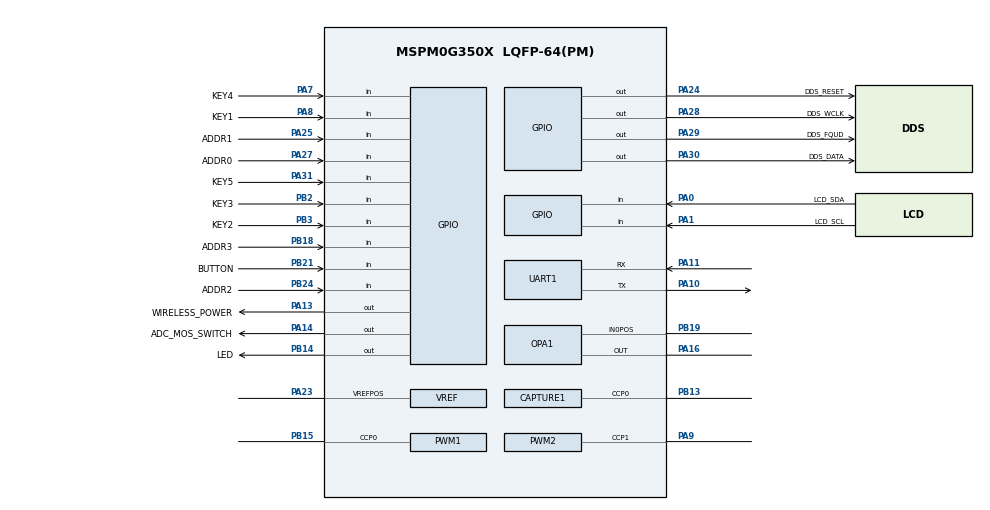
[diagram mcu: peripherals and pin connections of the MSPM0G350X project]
// @cliArgs --product "C:/ti/mspm0_sdk_2_01_00_03/.metadata/product.json" --device "MSPM0G350X" --package "LQFP-64(PM)" --part "Default"
// @versions {"tool":"1.20.0+3587"}

/**
 * Import the modules used in this configuration.
 */
const ADC12  = scripting.addModule("/ti/driverlib/ADC12", {}, false);
const ADC121 = ADC12.addInstance();
const ADC122 = ADC12.addInstance();
const Board  = scripting.addModule("/ti/driverlib/Board");
const CAPTURE = scripting.addModule("/ti/driverlib/CAPTURE", {}, false);
const CAPTURE1 = CAPTURE.addInstance();
const COMP   = scripting.addModule("/ti/driverlib/COMP", {}, false);
const COMP1  = COMP.addInstance();
const DAC12  = scripting.addModule("/ti/driverlib/DAC12");
const DMA    = scripting.addModule("/ti/driverlib/DMA");
const GPIO   = scripting.addModule("/ti/driverlib/GPIO", {}, false);
const GPIO1  = GPIO.addInstance();
const GPIO2  = GPIO.addInstance();
const GPIO3  = GPIO.addInstance();
const GPIO4  = GPIO.addInstance();
const GPIO5  = GPIO.addInstance();
const GPIO6  = GPIO.addInstance();
const OPA    = scripting.addModule("/ti/driverlib/OPA", {}, false);
const OPA1   = OPA.addInstance();
const PWM    = scripting.addModule("/ti/driverlib/PWM", {}, false);
const PWM1   = PWM.addInstance();
const PWM2   = PWM.addInstance();
const RTC    = scripting.addModule("/ti/driverlib/RTC");
const SYSCTL = scripting.addModule("/ti/driverlib/SYSCTL");
const TIMER  = scripting.addModule("/ti/driverlib/TIMER", {}, false);
const TIMER1 = TIMER.addInstance();
const TIMER2 = TIMER.addInstance();
const TIMER3 = TIMER.addInstance();
const UART   = scripting.addModule("/ti/driverlib/UART", {}, false);
const UART1  = UART.addInstance();
const VREF   = scripting.addModule("/ti/driverlib/VREF");

/**
 * Write custom configuration values to the imported modules.
 */
const gate8  = system.clockTree["MFPCLKGATE"];
gate8.enable = true;

ADC121.$name                          = "ADC12_0";
ADC121.repeatMode                     = true;
ADC121.trigSrc                        = "DL_ADC12_TRIG_SRC_EVENT";
ADC121.adcMem0chansel                 = "DL_ADC12_INPUT_CHAN_7";
ADC121.adcMem0vref                    = "VREF";
ADC121.sampleTime0                    = "500ns";
ADC121.powerDownMode                  = "DL_ADC12_POWER_DOWN_MODE_MANUAL";
ADC121.configureDMA                   = true;
ADC121.sampCnt                        = 1;
ADC121.enabledDMATriggers             = ["DL_ADC12_DMA_MEM0_RESULT_LOADED"];
ADC121.enabledInterrupts              = ["DL_ADC12_INTERRUPT_DMA_DONE"];
ADC121.subChanID                      = 1;
ADC121.peripheral.$assign             = "ADC0";
ADC121.peripheral.adcPin7.$assign     = "PA22";
ADC121.adcPin7Config.$name            = "ti_driverlib_gpio_GPIOPinGeneric0";
ADC121.DMA_CHANNEL.$name              = "DMA_CH0";
ADC121.DMA_CHANNEL.addressMode        = "f2b";
ADC121.DMA_CHANNEL.srcLength          = "HALF_WORD";
ADC121.DMA_CHANNEL.dstLength          = "HALF_WORD";
ADC121.DMA_CHANNEL.transferMode       = "FULL_CH_REPEAT_SINGLE";
ADC121.DMA_CHANNEL.peripheral.$assign = "DMA_CH0";

ADC122.$name                          = "ADC12_1";
ADC122.repeatMode                     = true;
ADC122.trigSrc                        = "DL_ADC12_TRIG_SRC_EVENT";
ADC122.adcMem0chansel                 = "DL_ADC12_INPUT_CHAN_7";
ADC122.adcMem0vref                    = "VREF";
ADC122.sampleTime0                    = "500ns";
ADC122.powerDownMode                  = "DL_ADC12_POWER_DOWN_MODE_MANUAL";
ADC122.configureDMA                   = true;
ADC122.sampCnt                        = 1;
ADC122.enabledDMATriggers             = ["DL_ADC12_DMA_MEM0_RESULT_LOADED"];
ADC122.enabledInterrupts              = ["DL_ADC12_INTERRUPT_DMA_DONE"];
ADC122.subChanID                      = 2;
ADC122.peripheral.$assign             = "ADC1";
ADC122.peripheral.adcPin7.$assign     = "PA21";
ADC122.adcPin7Config.$name            = "ti_driverlib_gpio_GPIOPinGeneric1";
ADC122.DMA_CHANNEL.$name              = "DMA_CH1";
ADC122.DMA_CHANNEL.addressMode        = "f2b";
ADC122.DMA_CHANNEL.srcLength          = "HALF_WORD";
ADC122.DMA_CHANNEL.dstLength          = "HALF_WORD";
ADC122.DMA_CHANNEL.transferMode       = "FULL_CH_REPEAT_SINGLE";
ADC122.DMA_CHANNEL.peripheral.$assign = "DMA_CH1";


DAC12.dacOutputPinEn     = true;
DAC12.dacConfigureDMA    = true;
DAC12.dacSampleTimerEn   = false;
DAC12.dacSampleTimerRate = "1M";
DAC12.dacOutput12        = 2048;
DAC12.dacFIFOEn          = true;
DAC12.dacAmplifier       = "ON";
DAC12.dacFIFOThresh      = "TWO_QTRS_EMPTY";
DAC12.DMA_CHANNEL.$name  = "DMA_DAC";
DAC12.DMA_CHANNEL.transferMode = "FULL_CH_REPEAT_SINGLE";
DAC12.DMA_CHANNEL.addressMode = "b2f";
DAC12.DMA_CHANNEL.srcLength = "HALF_WORD";
DAC12.DMA_CHANNEL.dstLength = "HALF_WORD";
DAC12.DMA_CHANNEL.peripheral.$assign = "DMA_CH2";
DAC12.OutPinConfig.$name = "ti_driverlib_gpio_GPIOPinGeneric4";


GPIO1.$name                              = "KEY";
GPIO1.associatedPins.create(5);
GPIO1.associatedPins[0].$name            = "KEY1";
GPIO1.associatedPins[0].direction        = "INPUT";
GPIO1.associatedPins[0].assignedPort     = "PORTA";
GPIO1.associatedPins[0].assignedPin      = "8";
GPIO1.associatedPins[0].internalResistor = "PULL_UP";
GPIO1.associatedPins[0].pin.$assign      = "PA8";
GPIO1.associatedPins[1].$name            = "KEY2";
GPIO1.associatedPins[1].direction        = "INPUT";
GPIO1.associatedPins[1].assignedPort     = "PORTB";
GPIO1.associatedPins[1].assignedPin      = "3";
GPIO1.associatedPins[1].internalResistor = "PULL_UP";
GPIO1.associatedPins[1].pin.$assign      = "PB3";
GPIO1.associatedPins[2].$name            = "KEY3";
GPIO1.associatedPins[2].direction        = "INPUT";
GPIO1.associatedPins[2].assignedPort     = "PORTB";
GPIO1.associatedPins[2].assignedPin      = "2";
GPIO1.associatedPins[2].internalResistor = "PULL_UP";
GPIO1.associatedPins[2].pin.$assign      = "PB2";
GPIO1.associatedPins[3].$name            = "KEY4";
GPIO1.associatedPins[3].direction        = "INPUT";
GPIO1.associatedPins[3].assignedPort     = "PORTA";
GPIO1.associatedPins[3].assignedPin      = "7";
GPIO1.associatedPins[3].internalResistor = "PULL_UP";
GPIO1.associatedPins[3].pin.$assign      = "PA7";
GPIO1.associatedPins[4].$name            = "KEY5";
GPIO1.associatedPins[4].direction        = "INPUT";
GPIO1.associatedPins[4].assignedPort     = "PORTA";
GPIO1.associatedPins[4].assignedPin      = "31";
GPIO1.associatedPins[4].internalResistor = "PULL_UP";
GPIO1.associatedPins[4].pin.$assign      = "PA31";

GPIO2.$name                                      = "KEY_LED";
GPIO2.associatedPins.create(2);
GPIO2.associatedPins[0].$name                    = "LED";
GPIO2.associatedPins[0].direction                = "OUTPUT";
GPIO2.associatedPins[0].initialValue             = "CLEARED";
GPIO2.associatedPins[0].assignedPort             = "PORTB";
GPIO2.associatedPins[0].assignedPortSegment      = "Lower";
GPIO2.associatedPins[0].assignedPin              = "14";
GPIO2.associatedPins[0].pin.$assign              = "PB14";
GPIO2.associatedPins[1].$name                    = "BUTTON";
GPIO2.associatedPins[1].direction                = "INPUT";
GPIO2.associatedPins[1].internalResistor         = "PULL_UP";
GPIO2.associatedPins[1].hysteresisControl        = "DISABLE";
GPIO2.associatedPins[1].assignedPort             = "PORTB";
GPIO2.associatedPins[1].assignedPortSegment      = "Upper";
GPIO2.associatedPins[1].assignedPin              = "21";
GPIO2.associatedPins[1].pin.$assign              = "PB21";

/* MSP-LITO-G3507 external OLED bus; R7/R8 provide 2.2 kOhm pulls to 3.3 V. */
GPIO3.$name                                      = "I2C_LCD_PINS";
GPIO3.associatedPins.create(2);
GPIO3.associatedPins[0].$name                    = "LCD_SDA";
GPIO3.associatedPins[0].direction                = "INPUT";
GPIO3.associatedPins[0].hysteresisControl        = "DISABLE";
GPIO3.associatedPins[0].assignedPort             = "PORTA";
GPIO3.associatedPins[0].assignedPortSegment      = "Lower";
GPIO3.associatedPins[0].assignedPin              = "0";
GPIO3.associatedPins[0].pin.$assign              = "PA0";
GPIO3.associatedPins[1].$name                    = "LCD_SCL";
GPIO3.associatedPins[1].direction                = "INPUT";
GPIO3.associatedPins[1].hysteresisControl        = "DISABLE";
GPIO3.associatedPins[1].assignedPort             = "PORTA";
GPIO3.associatedPins[1].assignedPortSegment      = "Lower";
GPIO3.associatedPins[1].assignedPin              = "1";
GPIO3.associatedPins[1].pin.$assign              = "PA1";

/* Active low-power measurement board controls.  PA13 and PA14 are not
 * available to the legacy AD9833 backend in this hardware profile. */
GPIO4.$name                                      = "BOARD_CONTROL";
GPIO4.associatedPins.create(2);
GPIO4.associatedPins[0].$name                    = "WIRELESS_POWER";
GPIO4.associatedPins[0].direction                = "OUTPUT";
GPIO4.associatedPins[0].initialValue             = "CLEARED";
GPIO4.associatedPins[0].assignedPort             = "PORTA";
GPIO4.associatedPins[0].assignedPortSegment      = "Lower";
GPIO4.associatedPins[0].assignedPin              = "13";
GPIO4.associatedPins[0].pin.$assign              = "PA13";
GPIO4.associatedPins[1].$name                    = "ADC_MOS_SWITCH";
GPIO4.associatedPins[1].direction                = "OUTPUT";
GPIO4.associatedPins[1].initialValue             = "CLEARED";
GPIO4.associatedPins[1].assignedPort             = "PORTA";
GPIO4.associatedPins[1].assignedPortSegment      = "Lower";
GPIO4.associatedPins[1].assignedPin              = "14";
GPIO4.associatedPins[1].pin.$assign              = "PA14";

GPIO5.$name                                      = "ADDR_CODE";
GPIO5.associatedPins.create(4);
GPIO5.associatedPins[0].$name                    = "ADDR0";
GPIO5.associatedPins[0].direction                = "INPUT";
GPIO5.associatedPins[0].internalResistor         = "PULL_DOWN";
GPIO5.associatedPins[0].assignedPort             = "PORTA";
GPIO5.associatedPins[0].assignedPin              = "27";
GPIO5.associatedPins[0].pin.$assign              = "PA27";
GPIO5.associatedPins[1].$name                    = "ADDR1";
GPIO5.associatedPins[1].direction                = "INPUT";
GPIO5.associatedPins[1].internalResistor         = "PULL_DOWN";
GPIO5.associatedPins[1].assignedPort             = "PORTA";
GPIO5.associatedPins[1].assignedPin              = "25";
GPIO5.associatedPins[1].pin.$assign              = "PA25";
GPIO5.associatedPins[2].$name                    = "ADDR2";
GPIO5.associatedPins[2].direction                = "INPUT";
GPIO5.associatedPins[2].internalResistor         = "PULL_DOWN";
GPIO5.associatedPins[2].assignedPort             = "PORTB";
GPIO5.associatedPins[2].assignedPortSegment      = "Upper";
GPIO5.associatedPins[2].assignedPin              = "24";
GPIO5.associatedPins[2].pin.$assign              = "PB24";
GPIO5.associatedPins[3].$name                    = "ADDR3";
GPIO5.associatedPins[3].direction                = "INPUT";
GPIO5.associatedPins[3].internalResistor         = "PULL_DOWN";
GPIO5.associatedPins[3].assignedPort             = "PORTB";
GPIO5.associatedPins[3].assignedPortSegment      = "Upper";
GPIO5.associatedPins[3].assignedPin              = "18";
GPIO5.associatedPins[3].pin.$assign              = "PB18";

/* External DDS (AD9850-style, dropped module) software-serial control lines.
 * All four pins are free on the MSP-LITO-G3507.  Change only if the module
 * needs different wiring; keep pinmux ownership in SysConfig. */
GPIO6.$name                                      = "DDS_CTRL";
GPIO6.associatedPins.create(4);
GPIO6.associatedPins[0].$name                    = "DDS_WCLK";
GPIO6.associatedPins[0].direction                = "OUTPUT";
GPIO6.associatedPins[0].initialValue             = "CLEARED";
GPIO6.associatedPins[0].assignedPort             = "PORTA";
GPIO6.associatedPins[0].assignedPortSegment      = "Upper";
GPIO6.associatedPins[0].assignedPin              = "28";
GPIO6.associatedPins[0].pin.$assign              = "PA28";
GPIO6.associatedPins[1].$name                    = "DDS_FQUD";
GPIO6.associatedPins[1].direction                = "OUTPUT";
GPIO6.associatedPins[1].initialValue             = "CLEARED";
GPIO6.associatedPins[1].assignedPort             = "PORTA";
GPIO6.associatedPins[1].assignedPortSegment      = "Upper";
GPIO6.associatedPins[1].assignedPin              = "29";
GPIO6.associatedPins[1].pin.$assign              = "PA29";
GPIO6.associatedPins[2].$name                    = "DDS_DATA";
GPIO6.associatedPins[2].direction                = "OUTPUT";
GPIO6.associatedPins[2].initialValue             = "CLEARED";
GPIO6.associatedPins[2].assignedPort             = "PORTA";
GPIO6.associatedPins[2].assignedPortSegment      = "Upper";
GPIO6.associatedPins[2].assignedPin              = "30";
GPIO6.associatedPins[2].pin.$assign              = "PA30";
GPIO6.associatedPins[3].$name                    = "DDS_RESET";
GPIO6.associatedPins[3].direction                = "OUTPUT";
GPIO6.associatedPins[3].initialValue             = "CLEARED";
GPIO6.associatedPins[3].assignedPort             = "PORTA";
GPIO6.associatedPins[3].assignedPortSegment      = "Upper";
GPIO6.associatedPins[3].assignedPin              = "24";
GPIO6.associatedPins[3].pin.$assign              = "PA24";

SYSCTL.forceDefaultClkConfig = true;
SYSCTL.clockTreeEn           = true;
SYSCTL.MFPCLKEn              = true;
SYSCTL.LFCLKSource           = "LFXT";
SYSCTL.validateClkStatus     = false;
/* MSPM0G3507 legal default clock tree: SYSOSC -> MCLK/BUSCLK/CPUCLK at 32 MHz.
 * The board's populated 100 kOhm 0.1% ROSC is enabled by BoardClock_Init().
 * LFCLK runs from the on-board 32.768 kHz LFXT (PA3/PA4) to clock the RTC. */
const muxLfclkIn   = system.clockTree["EXLFMUX"];
muxLfclkIn.inputSelect = "EXLFMUX_XTAL";
const muxLfxt      = system.clockTree["LFXTMUX"];
muxLfxt.inputSelect = "LFXTMUX_TRUE";
const pinLfxt      = system.clockTree["LFXT"];
pinLfxt.enable     = true;
pinLfxt.inputFreq  = 32;

VREF.profile             = "INT_2_5_V";
VREF.vrefPosPinConfig.$name = "ti_driverlib_gpio_GPIOPinGeneric7";
VREF.peripheral.$assign  = "VREF";
VREF.peripheral.vrefPosPin.$assign = "PA23";

TIMER1.$name                       = "ADC_SAMPLE_TIMER";
TIMER1.timerMode                   = "PERIODIC";
TIMER1.timerStartTimer             = false;
TIMER1.timerPeriod                 = "78.125 us";
TIMER1.event1PublisherChannel      = 1;
TIMER1.event1ControllerInterruptEn = ["ZERO_EVENT"];
TIMER1.event2PublisherChannel      = 2;
TIMER1.event2ControllerInterruptEn = ["ZERO_EVENT"];
TIMER1.peripheral.$assign          = "TIMG0";

TIMER3.$name              = "LP_WAKE_TIMER";
TIMER3.timerMode          = "PERIODIC";
TIMER3.timerStartTimer    = false;
TIMER3.timerClkSrc        = "LFCLK";
TIMER3.timerPeriod        = "500 ms";
TIMER3.interrupts         = ["ZERO"];
TIMER3.peripheral.$assign = "TIMG8";

UART1.$name                            = "UART_DEBUG";
UART1.targetBaudRate                   = 115200;
UART1.enableFIFO                       = true;
UART1.enabledInterrupts                = ["RX"];
UART1.peripheral.$assign               = "UART0";
UART1.peripheral.rxPin.$assign         = "PA11";
UART1.peripheral.txPin.$assign         = "PA10";
UART1.txPinConfig.$name                = "ti_driverlib_gpio_GPIOPinGeneric2";
UART1.txPinConfig.direction            = scripting.forceWrite("OUTPUT");
UART1.txPinConfig.hideOutputInversion  = scripting.forceWrite(false);
UART1.txPinConfig.onlyInternalResistor = scripting.forceWrite(false);
UART1.txPinConfig.passedPeripheralType = scripting.forceWrite("Digital");
UART1.rxPinConfig.$name                = "ti_driverlib_gpio_GPIOPinGeneric3";
UART1.rxPinConfig.hideOutputInversion  = scripting.forceWrite(false);
UART1.rxPinConfig.onlyInternalResistor = scripting.forceWrite(false);
UART1.rxPinConfig.passedPeripheralType = scripting.forceWrite("Digital");

/* Frequency meter: TIMG12 32-bit PERIOD capture on PB13 (free pin).
 * Period capture measures the time between two consecutive input edges in
 * hardware, so no ISR reload is needed and interrupt latency does not skew
 * the measurement (unlike EDGE_TIME which needs a manual reload). */
CAPTURE1.$name                      = "FREQ_CAPTURE";
CAPTURE1.timerClkSrc                = "BUSCLK";
CAPTURE1.timerClkDiv                = 1;
CAPTURE1.timerClkPrescale           = 1;
CAPTURE1.timerPeriod                = "1 s";
CAPTURE1.captMode                   = "PERIOD_CAPTURE";
CAPTURE1.interrupts                 = ["CC0_DN","ZERO"];
CAPTURE1.peripheral.$assign         = "TIMG12";
CAPTURE1.peripheral.ccp0Pin.$assign = "PB13";
CAPTURE1.ccp0PinConfig.$name        = "ti_driverlib_gpio_GPIOPinFreqCap0";

/* Square-wave generator: TIMG7 PWM edge mode, 50% duty, PB15 out (free pin). */
PWM1.$name                      = "SQUARE_TIMER";
PWM1.clockPrescale              = 1;
PWM1.timerCount                 = 32000;
PWM1.ccIndex                    = [0];
PWM1.peripheral.$assign         = "TIMG7";
PWM1.peripheral.ccp0Pin.$assign = "PB15";
PWM1.ccp0PinConfig.$name        = "ti_driverlib_gpio_GPIOPinSquare0";
PWM1.PWM_CHANNEL_0.$name        = "ti_driverlib_pwm_PWMTimerSquareCC0";
PWM1.PWM_CHANNEL_0.dutyCycle    = 50;
PWM1.PWM_CHANNEL_0.ccValue      = 16000;

/* General PWM output: TIMA0 CCP1 on PA9 (free pin). */
PWM2.$name                      = "PWM_TIMER";
PWM2.clockPrescale              = 1;
PWM2.timerCount                 = 32000;
PWM2.ccIndex                    = [1];
PWM2.peripheral.$assign         = "TIMA0";
PWM2.peripheral.ccp1Pin.$assign = "PA9";
PWM2.ccp1PinConfig.$name        = "ti_driverlib_gpio_GPIOPinPwm1";
PWM2.PWM_CHANNEL_1.$name        = "ti_driverlib_pwm_PWMTimerPwmCC1";
PWM2.PWM_CHANNEL_1.dutyCycle    = 50;
PWM2.PWM_CHANNEL_1.ccValue      = 16000;

/* CV/CC control tick: TIMG6 periodic 50 us (20 kHz) zero-event interrupt. */
TIMER2.$name                      = "PSU_CTRL_TIMER";
TIMER2.timerMode                  = "PERIODIC";
TIMER2.timerStartTimer            = false;
TIMER2.timerPeriod                = "50 us";
TIMER2.interrupts                 = ["ZERO"];
TIMER2.peripheral.$assign         = "TIMG6";

/* RTC on default LFCLK (calendar readout for MeterRecord timestamps). */
RTC.calYear            = 2026;
RTC.calMonth           = "1";
RTC.calDOM             = 1;
RTC.calHour            = 0;
RTC.calMin             = 0;
RTC.calSec             = 0;
RTC.peripheral.$assign = "RTC";

/* OPA1 non-inverting PGA 2x: IN0+=PB19, OUT=PA16 (both free).  The inverting
 * input is the internal RTAP ladder (NSEL=RTAP), no external pin needed. */
OPA1.$name                        = "OPA_0";
OPA1.cfg0OutputPin                = "ENABLED";
OPA1.cfg0PSELChannel              = "IN0_POS";
OPA1.cfg0NSELChannel              = "RTAP";
OPA1.cfg0MSELChannel              = "GND";
OPA1.cfg0Gain                     = "N1_P2";
OPA1.peripheral.$assign           = "OPA1";
OPA1.peripheral.In0PosPin.$assign = "PB19";
OPA1.peripheral.OutPin.$assign    = "PA16";

/* COMP1 threshold comparator: IN0+=PB26, IN0-=PB27 (both free). */
COMP1.$name                      = "COMP_0";
COMP1.compMode                   = "DL_COMP_MODE_FAST";
COMP1.hysteresis                 = "DL_COMP_HYSTERESIS_NONE";
COMP1.vSource                    = "DL_COMP_REF_SOURCE_VDDA_DAC";
COMP1.controlSelect              = "DL_COMP_DAC_CONTROL_SW";
COMP1.channelEnable              = ["POS","NEG"];
COMP1.enabledInterrupts          = ["DL_COMP_INTERRUPT_OUTPUT_EDGE"];
COMP1.peripheral.$assign         = "COMP1";
COMP1.peripheral.compPinPos0.$assign = "PB26";
COMP1.peripheral.compPinNeg0.$assign = "PB27";

/**
 * Pinmux solution for unlocked pins/peripherals. This ensures that minor changes to the automatic solver in a future
 * version of the tool will not impact the pinmux you originally saw.  These lines can be completely deleted in order to
 * re-solve from scratch.
 */
Board.peripheral.$suggestSolution                     = "DEBUGSS";
Board.peripheral.swclkPin.$suggestSolution            = "PA20";
Board.peripheral.swdioPin.$suggestSolution            = "PA19";
DAC12.peripheral.$suggestSolution                     = "DAC0";
DAC12.peripheral.OutPin.$suggestSolution              = "PA15";
